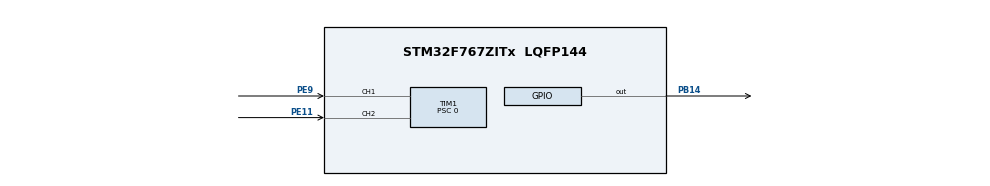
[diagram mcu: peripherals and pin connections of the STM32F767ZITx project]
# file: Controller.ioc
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Mcu.Family=STM32F7
Mcu.Name=STM32F767ZITx
Mcu.Package=LQFP144
NVIC.PriorityGroup=NVIC_PRIORITYGROUP_4
NVIC.TIM1_UP_TIM10_IRQn=true\:0\:0\:false\:false\:true\:true\:true\:true
NVIC.TIM2_IRQn=true\:0\:0\:false\:false\:true\:true\:true\:true
PB14.Signal=GPIO_Output
PB8.Signal=I2C1_SCL
PB9.Signal=I2C1_SDA
PE11.Signal=S_TIM1_CH2
PE9.Signal=S_TIM1_CH1
ProjectManager.HeapSize=0x200
ProjectManager.StackSize=0x400
ProjectManager.TargetToolchain=STM32CubeIDE
RCC.HSE_VALUE=25000000
RCC.HSI_VALUE=16000000
RCC.LSE_VALUE=32768
RCC.USBFreq_Value=96000000
RCC.VCOOutputFreq_Value=192000000
SH.S_TIM1_CH1.0=TIM1_CH1,Encoder_Interface
SH.S_TIM1_CH2.0=TIM1_CH2,Encoder_Interface
TIM1.AutoReloadPreload=TIM_AUTORELOAD_PRELOAD_ENABLE
TIM1.EncoderMode=TIM_ENCODERMODE_TI12
TIM1.Prescaler=0
TIM2.Period=999
TIM2.Prescaler=159
VP_TIM2_VS_ClockSourceINT.Mode=Internal
board=custom

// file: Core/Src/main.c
/* USER CODE BEGIN Header */
/**
  ******************************************************************************
  * @file           : main.c
  * @brief          : Main program body
  ******************************************************************************
  */
/* USER CODE END Header */
#include "main.h"

TIM_HandleTypeDef htim1;
TIM_HandleTypeDef htim2;

/* USER CODE BEGIN PV */
// --- PID ve Kontrol Değişkenleri ---
float actual = 0.0f;
float speed_onceki = 0.0f;
float referance = 60.0f; // Hedef RPM veya Pulse/dt
float error = 0.0f;

float turev = 0.0f;
float turev_filtreli = 0.0f;
float alpha = 0.02f;      // Filtre katsayısı (Gürültüye göre ayarla)
const float dt = 0.01f;  // 10ms = 0.01s

float integral_sonuc = 0.0f;
float pwm=0.0f;

// Enkoder Sabitleri
#define ENCODER_PPR 1024
#define TICKS_PER_REV (ENCODER_PPR * 4) // X4 modu
/* USER CODE END PV */

void SystemClock_Config(void);
static void MX_GPIO_Init(void);
static void MX_TIM1_Init(void);
static void MX_TIM2_Init(void);

int main(void)
{

  /* MCU Configuration--------------------------------------------------------*/

  /* Reset of all peripherals, Initializes the Flash interface and the Systick. */
  HAL_Init();

  /* Configure the system clock */
  SystemClock_Config();

  /* Initialize all configured peripherals */
  MX_GPIO_Init();
  MX_TIM1_Init();
  MX_TIM2_Init();
  /* USER CODE BEGIN 2 */
  // Değişkenleri sıfırla
  speed_onceki = 0.0f;
  integral_sonuc = 0.0f;
  error = 0.0f;

  // Timer'ları Başlat
  HAL_TIM_Encoder_Start(&htim1, TIM_CHANNEL_ALL); // Donanımsal sayıcıyı aç
  HAL_TIM_Base_Start_IT(&htim2);                 // 10ms kesmesini başlat
  /* USER CODE END 2 */

  /* Infinite loop */
  while (1)
  {

  }
}

void SystemClock_Config(void)
{
  RCC_OscInitTypeDef RCC_OscInitStruct = {0};
  RCC_ClkInitTypeDef RCC_ClkInitStruct = {0};

  /** Configure the main internal regulator output voltage
  */
  __HAL_RCC_PWR_CLK_ENABLE();
  __HAL_PWR_VOLTAGESCALING_CONFIG(PWR_REGULATOR_VOLTAGE_SCALE3);

  /** Initializes the RCC Oscillators according to the specified parameters
  * in the RCC_OscInitTypeDef structure.
  */
  RCC_OscInitStruct.OscillatorType = RCC_OSCILLATORTYPE_HSI;
  RCC_OscInitStruct.HSIState = RCC_HSI_ON;
  RCC_OscInitStruct.HSICalibrationValue = RCC_HSICALIBRATION_DEFAULT;
  RCC_OscInitStruct.PLL.PLLState = RCC_PLL_NONE;
  if (HAL_RCC_OscConfig(&RCC_OscInitStruct) != HAL_OK)
  {
    Error_Handler();
  }

  /** Initializes the CPU, AHB and APB buses clocks
  */
  RCC_ClkInitStruct.ClockType = RCC_CLOCKTYPE_HCLK|RCC_CLOCKTYPE_SYSCLK
                              |RCC_CLOCKTYPE_PCLK1|RCC_CLOCKTYPE_PCLK2;
  RCC_ClkInitStruct.SYSCLKSource = RCC_SYSCLKSOURCE_HSI;
  RCC_ClkInitStruct.AHBCLKDivider = RCC_SYSCLK_DIV1;
  RCC_ClkInitStruct.APB1CLKDivider = RCC_HCLK_DIV1;
  RCC_ClkInitStruct.APB2CLKDivider = RCC_HCLK_DIV1;

  if (HAL_RCC_ClockConfig(&RCC_ClkInitStruct, FLASH_LATENCY_0) != HAL_OK)
  {
    Error_Handler();
  }
}

static void MX_TIM1_Init(void)
{

  TIM_Encoder_InitTypeDef sConfig = {0};
  TIM_MasterConfigTypeDef sMasterConfig = {0};

  htim1.Instance = TIM1;
  htim1.Init.Prescaler = 0;
  htim1.Init.CounterMode = TIM_COUNTERMODE_UP;
  htim1.Init.Period = 65535;
  htim1.Init.ClockDivision = TIM_CLOCKDIVISION_DIV1;
  htim1.Init.RepetitionCounter = 0;
  htim1.Init.AutoReloadPreload = TIM_AUTORELOAD_PRELOAD_ENABLE;
  sConfig.EncoderMode = TIM_ENCODERMODE_TI12;
  sConfig.IC1Polarity = TIM_ICPOLARITY_RISING;
  sConfig.IC1Selection = TIM_ICSELECTION_DIRECTTI;
  sConfig.IC1Prescaler = TIM_ICPSC_DIV1;
  sConfig.IC1Filter = 0;
  sConfig.IC2Polarity = TIM_ICPOLARITY_RISING;
  sConfig.IC2Selection = TIM_ICSELECTION_DIRECTTI;
  sConfig.IC2Prescaler = TIM_ICPSC_DIV1;
  sConfig.IC2Filter = 0;
  if (HAL_TIM_Encoder_Init(&htim1, &sConfig) != HAL_OK)
  {
    Error_Handler();
  }
  sMasterConfig.MasterOutputTrigger = TIM_TRGO_RESET;
  sMasterConfig.MasterOutputTrigger2 = TIM_TRGO2_RESET;
  sMasterConfig.MasterSlaveMode = TIM_MASTERSLAVEMODE_DISABLE;
  if (HAL_TIMEx_MasterConfigSynchronization(&htim1, &sMasterConfig) != HAL_OK)
  {
    Error_Handler();
  }

}

static void MX_TIM2_Init(void)
{

  TIM_ClockConfigTypeDef sClockSourceConfig = {0};
  TIM_MasterConfigTypeDef sMasterConfig = {0};

  htim2.Instance = TIM2;
  htim2.Init.Prescaler = 159;
  htim2.Init.CounterMode = TIM_COUNTERMODE_UP;
  htim2.Init.Period = 999;
  htim2.Init.ClockDivision = TIM_CLOCKDIVISION_DIV1;
  htim2.Init.AutoReloadPreload = TIM_AUTORELOAD_PRELOAD_DISABLE;
  if (HAL_TIM_Base_Init(&htim2) != HAL_OK)
  {
    Error_Handler();
  }
  sClockSourceConfig.ClockSource = TIM_CLOCKSOURCE_INTERNAL;
  if (HAL_TIM_ConfigClockSource(&htim2, &sClockSourceConfig) != HAL_OK)
  {
    Error_Handler();
  }
  sMasterConfig.MasterOutputTrigger = TIM_TRGO_RESET;
  sMasterConfig.MasterSlaveMode = TIM_MASTERSLAVEMODE_DISABLE;
  if (HAL_TIMEx_MasterConfigSynchronization(&htim2, &sMasterConfig) != HAL_OK)
  {
    Error_Handler();
  }

}

static void MX_GPIO_Init(void)
{
  GPIO_InitTypeDef GPIO_InitStruct = {0};

  /* GPIO Ports Clock Enable */
  __HAL_RCC_GPIOE_CLK_ENABLE();
  __HAL_RCC_GPIOB_CLK_ENABLE();

  /*Configure GPIO pin Output Level */
  HAL_GPIO_WritePin(GPIOB, GPIO_PIN_14, GPIO_PIN_RESET);

  /*Configure GPIO pin : PB14 */
  GPIO_InitStruct.Pin = GPIO_PIN_14;
  GPIO_InitStruct.Mode = GPIO_MODE_OUTPUT_PP;
  GPIO_InitStruct.Pull = GPIO_NOPULL;
  GPIO_InitStruct.Speed = GPIO_SPEED_FREQ_LOW;
  HAL_GPIO_Init(GPIOB, &GPIO_InitStruct);

  /*Configure GPIO pins : PB8 PB9 */
  GPIO_InitStruct.Pin = GPIO_PIN_8|GPIO_PIN_9;
  GPIO_InitStruct.Mode = GPIO_MODE_AF_OD;
  GPIO_InitStruct.Pull = GPIO_NOPULL;
  GPIO_InitStruct.Speed = GPIO_SPEED_FREQ_VERY_HIGH;
  GPIO_InitStruct.Alternate = GPIO_AF4_I2C1;
  HAL_GPIO_Init(GPIOB, &GPIO_InitStruct);

}

/* USER CODE BEGIN 4 */
/**
  * @brief  Timer Kesme Callback Fonksiyonu
  */
void HAL_TIM_PeriodElapsedCallback(TIM_HandleTypeDef *htim)
{
    // Kontrol periyodu (TIM2 - 100Hz/10ms)
    if(htim->Instance == TIM2)
    {

    	HAL_GPIO_WritePin(GPIOB, GPIO_PIN_14, GPIO_PIN_SET);
        // 1. Enkoder Farkını Oku (Hız Tespiti)
        // int16_t kullanımı 0-65535 geçişlerini otomatik düzeltir
        int16_t encoder_value = (int16_t)__HAL_TIM_GET_COUNTER(&htim1);
        __HAL_TIM_SET_COUNTER(&htim1, 0); // Bir sonraki fark için sıfırla

        // Pulse değerini RPM'e çevir (Opsiyonel)
        // actual = ((float)encoder_value / TICKS_PER_REV) * (60.0f / dt);
        actual = ((float)encoder_value / 4096.0f) * 6000.0f;

        // 2. Hata (Error) Hesaplama
        float onceki_error = error;
        error = referance - actual;

        // 3. Türev Hesaplama (Filtreli / de/dt)
        float error_turev_ham = (error - onceki_error) / dt;
        turev_filtreli = (alpha * error_turev_ham) + (1.0f - alpha) * turev_filtreli;
        turev = turev_filtreli;

        // 4. İntegral Hesaplama (Anti-Windup ile)
        integral_sonuc += error * dt;

        // İntegral Sınırlandırma (Sisteminize göre limitleri güncelleyin)
        if(integral_sonuc > 500.0f) integral_sonuc = 500.0f;
        if(integral_sonuc < -500.0f) integral_sonuc = -500.0f;

        // 5. Bir sonraki adım için sakla
        speed_onceki = actual;
        pwm = (10*error) +(2*turev)+(0.1*integral_sonuc);

    }
}
/* USER CODE END 4 */

void Error_Handler(void)
{
  __disable_irq();
  while (1)
  {
  }
}
